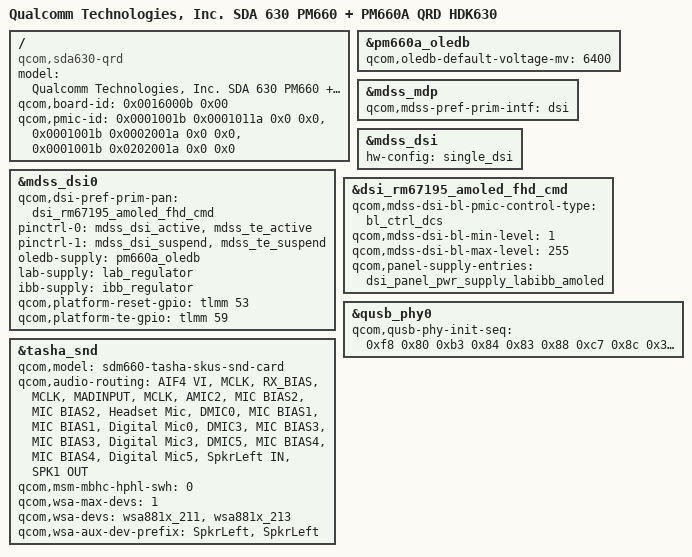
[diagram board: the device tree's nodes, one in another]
/* Copyright (c) 2017, The Linux Foundation. All rights reserved.
 *
 * This program is free software; you can redistribute it and/or modify
 * it under the terms of the GNU General Public License version 2 and
 * only version 2 as published by the Free Software Foundation.
 *
 * This program is distributed in the hope that it will be useful,
 * but WITHOUT ANY WARRANTY; without even the implied warranty of
 * MERCHANTABILITY or FITNESS FOR A PARTICULAR PURPOSE.  See the
 * GNU General Public License for more details.
 */


/dts-v1/;

#include "sda630.dtsi"
#include "sdm630-qrd.dtsi"
#include "msm-pm660a.dtsi"
#include "sdm660-external-codec.dtsi"

/ {
	model = "Qualcomm Technologies, Inc. SDA 630 PM660 + PM660A QRD HDK630";
	compatible = "qcom,sda630-qrd", "qcom,sda630", "qcom,qrd";
	qcom,board-id = <0x0016000b 0x00>;
	qcom,pmic-id = <0x0001001b 0x0001011a 0x0 0x0>,
			<0x0001001b 0x0002001a 0x0 0x0>,
			<0x0001001b 0x0202001a 0x0 0x0>;
};

&pm660a_oledb {
	status = "okay";
	qcom,oledb-default-voltage-mv = <6400>;
};

&mdss_mdp {
	qcom,mdss-pref-prim-intf = "dsi";
};

&mdss_dsi {
	hw-config = "single_dsi";
};

&mdss_dsi0 {
	qcom,dsi-pref-prim-pan = <&dsi_rm67195_amoled_fhd_cmd>;
	pinctrl-names = "mdss_default", "mdss_sleep";
	pinctrl-0 = <&mdss_dsi_active &mdss_te_active>;
	pinctrl-1 = <&mdss_dsi_suspend &mdss_te_suspend>;
	oledb-supply = <&pm660a_oledb>;
	lab-supply = <&lab_regulator>;
	ibb-supply = <&ibb_regulator>;
	qcom,platform-reset-gpio = <&tlmm 53 0>;
	qcom,platform-te-gpio = <&tlmm 59 0>;
};

&dsi_rm67195_amoled_fhd_cmd {
	qcom,mdss-dsi-bl-pmic-control-type = "bl_ctrl_dcs";
	qcom,mdss-dsi-bl-min-level = <1>;
	qcom,mdss-dsi-bl-max-level = <255>;
	qcom,panel-supply-entries = <&dsi_panel_pwr_supply_labibb_amoled>;
};

/delete-node/ &tasha_hph_en0;
/delete-node/ &tasha_hph_en1;

&qusb_phy0 {
	qcom,qusb-phy-init-seq = <0xf8 0x80
				0xb3 0x84
				0x83 0x88
				0xc7 0x8c
				0x30 0x08
				0x79 0x0c
				0x21 0x10
				0x14 0x9c
				0x9f 0x1c
				0x00 0x18>;
};

&tasha_snd {
	qcom,model = "sdm660-tasha-skus-snd-card";
	qcom,audio-routing =
		"AIF4 VI", "MCLK",
		"RX_BIAS", "MCLK",
		"MADINPUT", "MCLK",
		"AMIC2", "MIC BIAS2",
		"MIC BIAS2", "Headset Mic",
		"DMIC0", "MIC BIAS1",
		"MIC BIAS1", "Digital Mic0",
		"DMIC3", "MIC BIAS3",
		"MIC BIAS3", "Digital Mic3",
		"DMIC5", "MIC BIAS4",
		"MIC BIAS4", "Digital Mic5",
		"SpkrLeft IN", "SPK1 OUT";
	qcom,msm-mbhc-hphl-swh = <0>;
	/delete-property/ qcom,us-euro-gpios;
	/delete-property/ qcom,hph-en0-gpio;
	/delete-property/ qcom,hph-en1-gpio;
	qcom,wsa-max-devs = <1>;
	qcom,wsa-devs = <&wsa881x_211>, <&wsa881x_213>;
	qcom,wsa-aux-dev-prefix = "SpkrLeft", "SpkrLeft";
};
